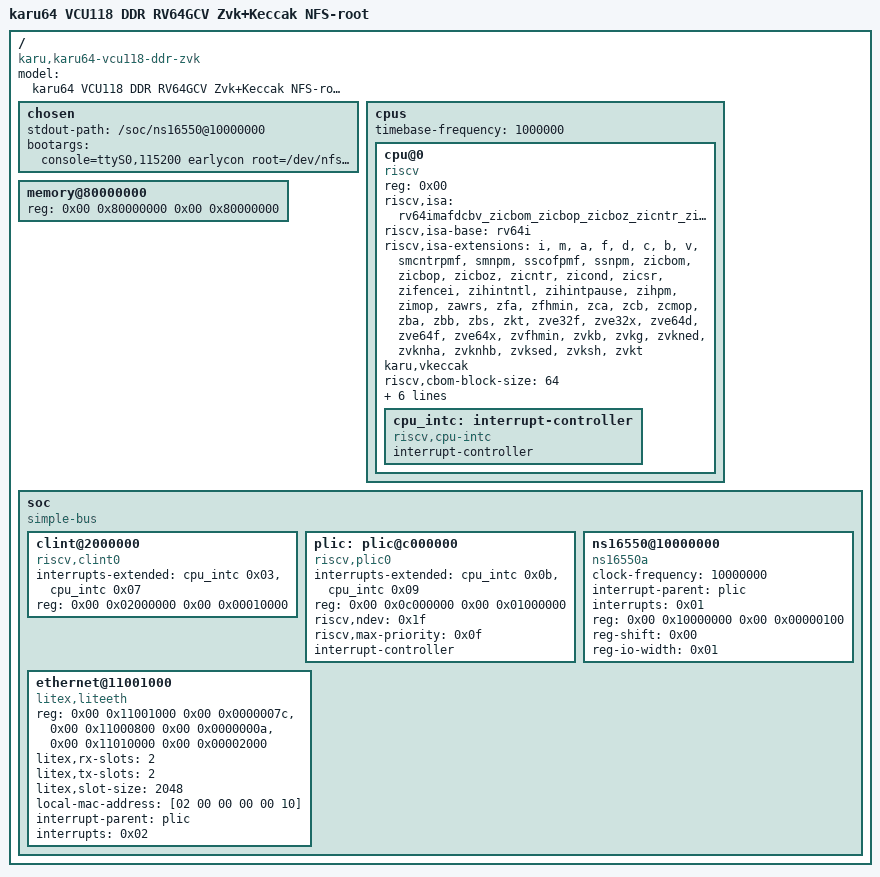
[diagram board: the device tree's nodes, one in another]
/dts-v1/;

/*
 * karu64 VCU118 DDR NFS-root board description for the RV64GCV + standard
 * Zvk RTL profile.  The custom vkeccak instruction is intentionally not listed
 * in riscv,isa because it has no standard ISA extension name.
 */

/ {
	#address-cells = <0x02>;
	#size-cells = <0x02>;
	compatible = "karu,karu64-vcu118-ddr-zvk";
	model = "karu64 VCU118 DDR RV64GCV Zvk+Keccak NFS-root";

	chosen {
		stdout-path = "/soc/ns16550@10000000";
		bootargs = "console=ttyS0,115200 earlycon root=/dev/nfs rw ip=192.168.42.10:192.168.42.1:192.168.42.1:255.255.255.0:karudeb:eth0:off nfsroot=192.168.42.1:/srv/nfs/karudeb,vers=3,tcp,nolock";
	};

	cpus {
		#address-cells = <0x01>;
		#size-cells = <0x00>;
		timebase-frequency = <1000000>;

		cpu@0 {
			device_type = "cpu";
			reg = <0x00>;
			status = "okay";
			compatible = "riscv";
			riscv,isa = "rv64imafdcbv_zicbom_zicbop_zicboz_zicntr_zicond_zicsr_zifencei_zihintntl_zihintpause_zihpm_zimop_zawrs_zfa_zfhmin_zca_zcb_zcmop_zba_zbb_zbs_zkt_zve32f_zve32x_zve64d_zve64f_zve64x_zvfhmin_zvkb_zvkg_zvkned_zvknha_zvknhb_zvksed_zvksh_zvkt_zvl256b_smcntrpmf_smnpm_sscofpmf_ssnpm";
			riscv,isa-base = "rv64i";
			riscv,isa-extensions = "i", "m", "a", "f", "d", "c", "b", "v",
					       "smcntrpmf", "smnpm", "sscofpmf", "ssnpm",
					       "zicbom", "zicbop", "zicboz",
					       "zicntr", "zicond", "zicsr", "zifencei",
					       "zihintntl", "zihintpause", "zihpm", "zimop",
					       "zawrs", "zfa", "zfhmin",
					       "zca", "zcb", "zcmop",
					       "zba", "zbb", "zbs", "zkt",
					       "zve32f", "zve32x", "zve64d", "zve64f",
					       "zve64x", "zvfhmin",
					       "zvkb", "zvkg", "zvkned", "zvknha",
					       "zvknhb", "zvksed", "zvksh", "zvkt";
			karu,vkeccak;
			riscv,cbom-block-size = <64>;
			riscv,cbop-block-size = <64>;
			riscv,cboz-block-size = <64>;
			mmu-type = "riscv,sv39";
			riscv,pmpregions = <0x10>;
			riscv,pmpgranularity = <0x04>;
			clock-frequency = <75000000>;

			cpu_intc: interrupt-controller {
				#address-cells = <0x02>;
				#interrupt-cells = <0x01>;
				interrupt-controller;
				compatible = "riscv,cpu-intc";
			};
		};
	};

	memory@80000000 {
		device_type = "memory";
		reg = <0x00 0x80000000 0x00 0x80000000>;	/* 2 GiB DDR4 */
	};

	soc {
		#address-cells = <0x02>;
		#size-cells = <0x02>;
		compatible = "simple-bus";
		ranges;

		clint@2000000 {
			compatible = "riscv,clint0";
			interrupts-extended = <&cpu_intc 0x03 &cpu_intc 0x07>;
			reg = <0x00 0x02000000 0x00 0x00010000>;
		};

		plic: plic@c000000 {
			compatible = "riscv,plic0";
			#address-cells = <0x02>;
			interrupts-extended = <&cpu_intc 0x0b &cpu_intc 0x09>;
			reg = <0x00 0x0c000000 0x00 0x01000000>;
			riscv,ndev = <0x1f>;
			riscv,max-priority = <0x0f>;
			#interrupt-cells = <0x01>;
			interrupt-controller;
		};

		ns16550@10000000 {
			compatible = "ns16550a";
			clock-frequency = <10000000>;
			interrupt-parent = <&plic>;
			interrupts = <0x01>;
			reg = <0x00 0x10000000 0x00 0x00000100>;
			reg-shift = <0x00>;
			reg-io-width = <0x01>;
		};

		ethernet@11001000 {
			compatible = "litex,liteeth";
			reg = <0x00 0x11001000 0x00 0x0000007c>,
			      <0x00 0x11000800 0x00 0x0000000a>,
			      <0x00 0x11010000 0x00 0x00002000>;
			reg-names = "mac", "mdio", "buffer";
			litex,rx-slots = <2>;
			litex,tx-slots = <2>;
			litex,slot-size = <2048>;
			local-mac-address = [02 00 00 00 00 10];
			interrupt-parent = <&plic>;
			interrupts = <0x02>;
		};
	};
};
